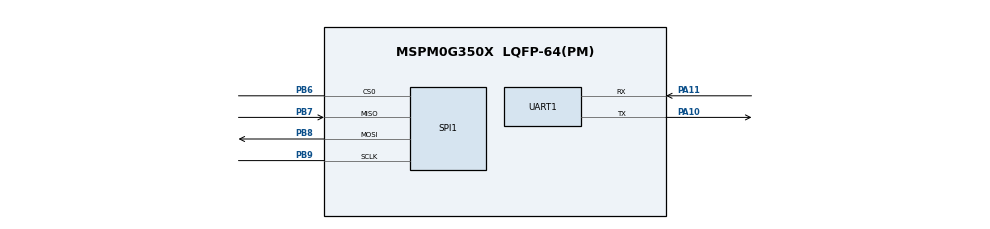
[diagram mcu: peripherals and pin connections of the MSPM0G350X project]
// @cliArgs --device "MSPM0G350X" --package "LQFP-64(PM)" --part "Default"
// @cliArgs --board /ti/boards/LP_MSPM0G3507 --rtos nortos

/**
 * Import the modules used in this configuration.
 */
const SPI    = scripting.addModule("/ti/driverlib/SPI", {}, false);
const SPI1   = SPI.addInstance();
const SYSCTL = scripting.addModule("/ti/driverlib/SYSCTL");
const UART   = scripting.addModule("/ti/driverlib/UART", {}, false);
const UART1  = UART.addInstance();

/**
 * Write custom configuration values to the imported modules.
 */
SPI1.$name                      = "SPI_0";
SPI1.enabledInterrupts          = ["PARITY_ERROR","RX","RX_FULL","RX_OVERFLOW","RX_TIMEOUT","TX","TX_UNDERFLOW"];
SPI1.rxFifoThreshold            = "DL_SPI_RX_FIFO_LEVEL_ONE_FRAME";
SPI1.peripheral.sclkPin.$assign = "PB9";
SPI1.peripheral.mosiPin.$assign = "PB8";
SPI1.peripheral.misoPin.$assign = "PB7";
SPI1.peripheral.cs0Pin.$assign  = "PB6";

const Board = scripting.addModule("/ti/driverlib/Board", {}, false);

SYSCTL.clockTreeEn           = true;
SYSCTL.forceDefaultClkConfig = true;

UART1.rxFifoThreshold                  = "DL_UART_RX_FIFO_LEVEL_ONE_ENTRY";
UART1.enableDMARX                      = false;
UART1.enableDMATX                      = false;
UART1.enabledInterrupts                = ["RX"];
UART1.$name                            = "UART_BRIDGE";
UART1.peripheral.$assign               = "UART0";
UART1.peripheral.rxPin.$assign         = "PA11";
UART1.peripheral.txPin.$assign         = "PA10";
